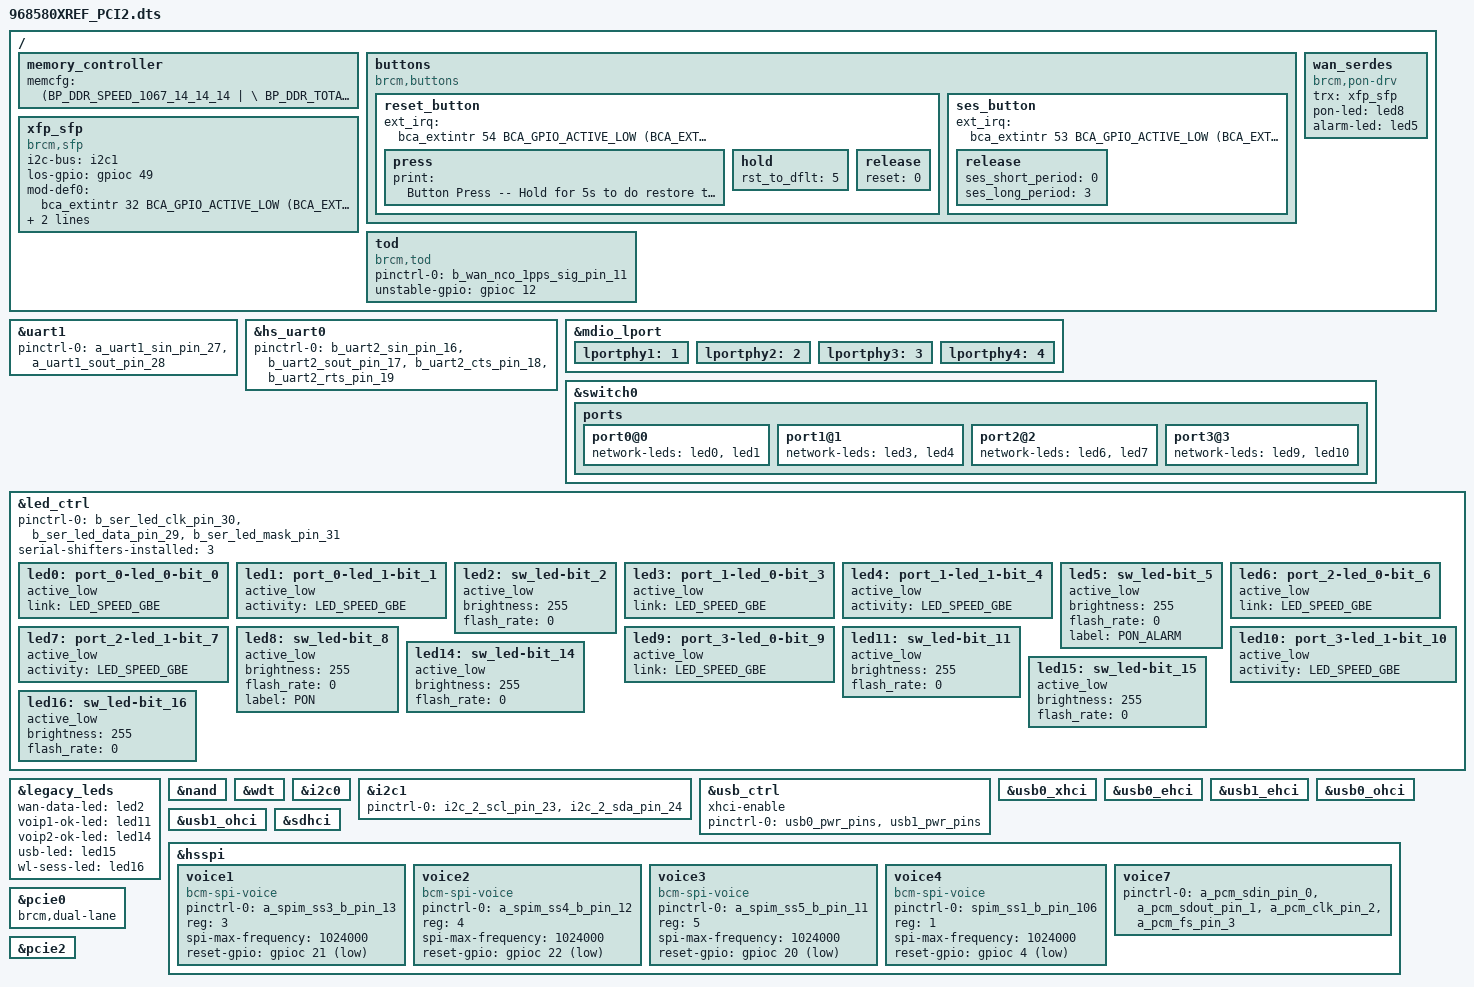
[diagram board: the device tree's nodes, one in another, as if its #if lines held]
#include "inc/68580.dtsi"

/ {
    memory_controller {
        memcfg = <(BP_DDR_SPEED_1067_14_14_14 | \
                   BP_DDR_TOTAL_SIZE_512MB    | \
                   BP_DDR_DEVICE_WIDTH_16     | \
                   BP_DDR_TOTAL_WIDTH_32BIT)>;
    };
};

/ {
    buttons {
        compatible = "brcm,buttons";
        reset_button {
            ext_irq = <&bca_extintr 54 BCA_GPIO_ACTIVE_LOW (BCA_EXTINTR_TYPE_LOW_LEVEL | BCA_EXTINTR_TYPE_SENSE_EDGE)>;
            press {
                print = "Button Press -- Hold for 5s to do restore to default";
   			};
            hold {
                rst_to_dflt = <5>;
            };
            release {
                reset = <0>;
            };	
        };
        ses_button {
            ext_irq = <&bca_extintr 53 BCA_GPIO_ACTIVE_LOW (BCA_EXTINTR_TYPE_LOW_LEVEL | BCA_EXTINTR_TYPE_SENSE_EDGE)>;
            release {
                ses_short_period = <0>;
                ses_long_period = <3>;
            };
        };
    };

    xfp_sfp: xfp_sfp {
        compatible = "brcm,sfp";
        i2c-bus = <&i2c1>;
        los-gpio = <&gpioc 49 GPIO_ACTIVE_HIGH>;
        mod-def0 = <&bca_extintr 32 BCA_GPIO_ACTIVE_LOW (BCA_EXTINTR_TYPE_BOTH_EDGE | BCA_EXTINTR_TYPE_SENSE_EDGE)>;
        tx-power-gpio = <&gpioc 50 GPIO_ACTIVE_HIGH>;
        tx-power-down-gpio = <&gpioc 55 GPIO_ACTIVE_HIGH>;
    };

    wan_serdes {
            compatible = "brcm,pon-drv";
            trx = <&xfp_sfp>;
            pon-led = <&led8>;
            alarm-led = <&led5>;
    };

    tod {
        compatible = "brcm,tod";
        pinctrl-names = "default";
        pinctrl-0 = <&b_wan_nco_1pps_sig_pin_11>;

        unstable-gpio = <&gpioc 12 GPIO_ACTIVE_HIGH>;
    };
};

#ifdef CONFIG_BCM_TIME_SYNC_MODULE
    /* UART 2*/
	&uart1 {
		pinctrl-0 = <&a_uart1_sin_pin_27 &a_uart1_sout_pin_28>;
	    status = "okay";
	};
#endif

&hs_uart0 {
    pinctrl-0 = <&b_uart2_sin_pin_16 &b_uart2_sout_pin_17 &b_uart2_cts_pin_18 &b_uart2_rts_pin_19>;
	status = "okay";
};

&mdio_lport {
        lportphy1:1 {
                status = "okay";
        };

        lportphy2:2 {
                status = "okay";
        };

        lportphy3:3 {
                status = "okay";
        };

        lportphy4:4 {
                status = "okay";
        };
};

&switch0 {
        ports {
                port0@0 {
                        status = "okay";
                        network-leds = <&led0 &led1>;
                };

                port1@1 {
                        status = "okay";
                        network-leds = <&led3 &led4>;
                };

                port2@2 {
                        status = "okay";
                        network-leds = <&led6 &led7>;
                };

                port3@3 {
                        status = "okay";
                        network-leds = <&led9 &led10>;
                };
        };
};

&led_ctrl {
    pinctrl-names = "default";
    pinctrl-0 = <&b_ser_led_clk_pin_30 &b_ser_led_data_pin_29 &b_ser_led_mask_pin_31>;
    serial-shifters-installed = <3>;
    
    led0: port_0-led_0-bit_0 {
              active_low;
              status = "okay";
              link = <LED_SPEED_GBE>;
          };
    led1: port_0-led_1-bit_1 {
              active_low;
              status = "okay";
              activity = <LED_SPEED_GBE>;
          };
    led2: sw_led-bit_2 {
              active_low; 
              brightness = <255>;
              flash_rate = <0>;
              status = "okay";
          };
    led3: port_1-led_0-bit_3 {
              active_low;
              status = "okay";
              link = <LED_SPEED_GBE>;
          };
    led4: port_1-led_1-bit_4 {
              active_low;
              status = "okay";
              activity = <LED_SPEED_GBE>;
          };
    led5: sw_led-bit_5 {
              active_low; 
              brightness = <255>;
              flash_rate = <0>;
              status = "okay";
              label = "PON_ALARM";
          };
    led6: port_2-led_0-bit_6 {
              active_low;
              status = "okay";
              link = <LED_SPEED_GBE>;
          };
    led7: port_2-led_1-bit_7 {
              active_low;
              status = "okay";
              activity = <LED_SPEED_GBE>;
          };
    led8: sw_led-bit_8 {
              active_low; 
              brightness = <255>;
              flash_rate = <0>;
              status = "okay";
              label = "PON";
          };
    led9: port_3-led_0-bit_9 {
              active_low;
              status = "okay";
              link = <LED_SPEED_GBE>;
          };
    led10: port_3-led_1-bit_10 {
               active_low;
               status = "okay";
               activity = <LED_SPEED_GBE>;
          };
    led11: sw_led-bit_11 {
              active_low; 
              brightness = <255>;
              flash_rate = <0>;
              status = "okay";
          };
    led14: sw_led-bit_14 {
              active_low; 
              brightness = <255>;
              flash_rate = <0>;
              status = "okay";
          };
    led15: sw_led-bit_15 {
              active_low; 
              brightness = <255>;
              flash_rate = <0>;
              status = "okay";
          };
    led16: sw_led-bit_16 {
              active_low; 
              brightness = <255>;
              flash_rate = <0>;
              status = "okay";
          };
};

&legacy_leds {
    wan-data-led = <&led2>;
    voip1-ok-led = <&led11>;
    voip2-ok-led = <&led14>;
    usb-led = <&led15>;
    wl-sess-led = <&led16>;
};

&nand {
	status = "okay";
};
&wdt {
	status = "okay";
};
&i2c0 {
    status = "okay";
};
&i2c1 {
    pinctrl-0 = <&i2c_2_scl_pin_23 &i2c_2_sda_pin_24>;
    pinctrl-names = "default";
    status = "okay";
};

&usb_ctrl {
	status = "okay";
    xhci-enable;
    pinctrl-names = "default";
    pinctrl-0 = <&usb0_pwr_pins &usb1_pwr_pins>;
};
&usb0_xhci {
	status = "okay";
};
&usb0_ehci {
	status = "okay";
};
&usb1_ehci {
    status = "okay";
};
&usb0_ohci {
	status = "okay";
};
&usb1_ohci {
	status = "okay";
};
&sdhci {
	status = "okay";
};
&hsspi {
	status = "okay";

    voice1 {
        pinctrl-0 = <&a_spim_ss3_b_pin_13>;
        pinctrl-names = "default";
        compatible = "bcm-spi-voice";
        reg = <3>; /* chip select 3 */
        spi-max-frequency = <1024000>;
        reset-gpio = <&gpioc 21 GPIO_ACTIVE_LOW>;
    };

    voice2 {
        pinctrl-0 = <&a_spim_ss4_b_pin_12>;
        pinctrl-names = "default";
        compatible = "bcm-spi-voice";
        reg = <4>; /* chip select 4 */
        spi-max-frequency = <1024000>;
        reset-gpio = <&gpioc 22 GPIO_ACTIVE_LOW>;
    };

    voice3 {
        pinctrl-0 = <&a_spim_ss5_b_pin_11>;
        pinctrl-names = "default";
        compatible = "bcm-spi-voice";
        reg = <5>; /* chip select 5 */
        spi-max-frequency = <1024000>;
        reset-gpio = <&gpioc 20 GPIO_ACTIVE_LOW>;
    };

    voice4 {
        pinctrl-0 = <&spim_ss1_b_pin_106>;
        pinctrl-names = "default";
        compatible = "bcm-spi-voice";
        reg = <1>; /* chip select 1 */
        spi-max-frequency = <1024000>;
        reset-gpio = <&gpioc 4 GPIO_ACTIVE_LOW>;
    };

    voice7 {
        pinctrl-0 = <&a_pcm_sdin_pin_0 &a_pcm_sdout_pin_1 &a_pcm_clk_pin_2 &a_pcm_fs_pin_3>;
        pinctrl-names = "default";
    };
};

&pcie0 {
	brcm,dual-lane;
	status = "okay";
};
&pcie2 {
	status = "okay";
};

